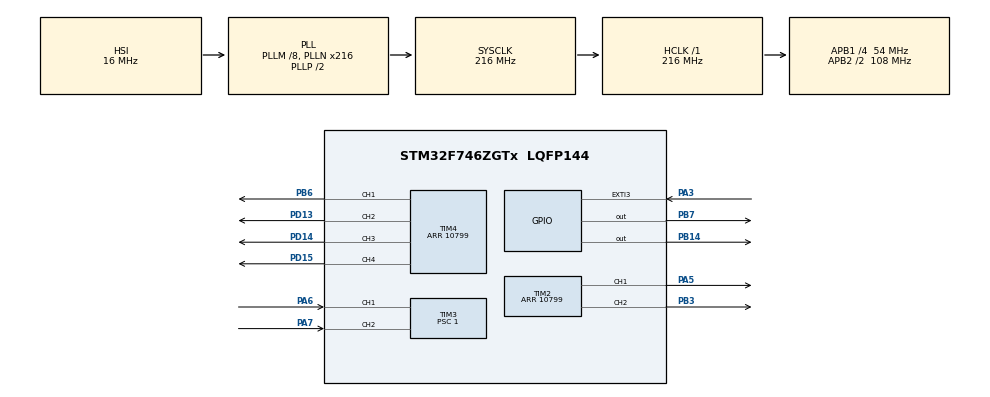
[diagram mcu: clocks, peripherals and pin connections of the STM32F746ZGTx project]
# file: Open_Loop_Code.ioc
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Mcu.Family=STM32F7
Mcu.Name=STM32F746ZGTx
Mcu.Package=LQFP144
NVIC.EXTI3_IRQn=true\:0\:0\:false\:false\:true\:true\:true
NVIC.PriorityGroup=NVIC_PRIORITYGROUP_4
NVIC.TIM5_IRQn=true\:0\:0\:false\:false\:true\:true\:true
PA3.Signal=GPXTI3
PA5.Signal=S_TIM2_CH1_ETR
PA6.Signal=S_TIM3_CH1
PA7.Signal=S_TIM3_CH2
PB14.Signal=GPIO_Output
PB3.Signal=S_TIM2_CH2
PB6.Signal=S_TIM4_CH1
PB7.Signal=GPIO_Output
PD13.Signal=S_TIM4_CH2
PD14.Signal=S_TIM4_CH3
PD15.Signal=S_TIM4_CH4
ProjectManager.HeapSize=0x200
ProjectManager.StackSize=0x400
ProjectManager.TargetToolchain=MDK-ARM V5.27
RCC.AHBFreq_Value=216000000
RCC.APB1CLKDivider=RCC_HCLK_DIV4
RCC.APB1Freq_Value=54000000
RCC.APB1TimFreq_Value=108000000
RCC.APB2CLKDivider=RCC_HCLK_DIV2
RCC.APB2Freq_Value=108000000
RCC.APB2TimFreq_Value=216000000
RCC.CortexFreq_Value=216000000
RCC.HCLKFreq_Value=216000000
RCC.HSE_VALUE=25000000
RCC.HSI_VALUE=16000000
RCC.LSE_VALUE=32768
RCC.PLLM=8
RCC.PLLN=216
RCC.SYSCLKFreq_VALUE=216000000
RCC.SYSCLKSource=RCC_SYSCLKSOURCE_PLLCLK
RCC.USBFreq_Value=216000000
RCC.VCOOutputFreq_Value=432000000
SH.S_TIM2_CH1_ETR.0=TIM2_CH1,PWM Generation1 CH1
SH.S_TIM2_CH2.0=TIM2_CH2,PWM Generation2 CH2
SH.S_TIM3_CH1.0=TIM3_CH1,Encoder_Interface
SH.S_TIM3_CH2.0=TIM3_CH2,Encoder_Interface
SH.S_TIM4_CH1.0=TIM4_CH1,PWM Generation1 CH1
SH.S_TIM4_CH2.0=TIM4_CH2,PWM Generation2 CH2
SH.S_TIM4_CH3.0=TIM4_CH3,PWM Generation3 CH3
SH.S_TIM4_CH4.0=TIM4_CH4,PWM Generation4 CH4
TIM2.Channel-PWM\ Generation1\ CH1=TIM_CHANNEL_1
TIM2.Channel-PWM\ Generation2\ CH2=TIM_CHANNEL_2
TIM2.CounterMode=TIM_COUNTERMODE_CENTERALIGNED1
TIM2.Period=10799
TIM3.EncoderMode=TIM_ENCODERMODE_TI12
TIM3.Period=65535
TIM3.Prescaler=1
TIM4.Channel-PWM\ Generation1\ CH1=TIM_CHANNEL_1
TIM4.Channel-PWM\ Generation2\ CH2=TIM_CHANNEL_2
TIM4.Channel-PWM\ Generation3\ CH3=TIM_CHANNEL_3
TIM4.Channel-PWM\ Generation4\ CH4=TIM_CHANNEL_4
TIM4.CounterMode=TIM_COUNTERMODE_CENTERALIGNED1
TIM4.Period=10799
TIM5.Period=49
TIM5.Prescaler=215
VP_TIM5_VS_ClockSourceINT.Mode=Internal
board=custom

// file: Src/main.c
/* USER CODE BEGIN Header */
/**
  ******************************************************************************
  * @file           : main.c
  * @brief          : Main program body
  ******************************************************************************
  * @attention
  *
  * <h2><center>&copy; Copyright (c) 2021 STMicroelectronics.
  * All rights reserved.</center></h2>
  *
  * This software component is licensed by ST under BSD 3-Clause license,
  * the "License"; You may not use this file except in compliance with the
  * License. You may obtain a copy of the License at:
  *                        opensource.org/licenses/BSD-3-Clause
  *
  ******************************************************************************
  */
/* USER CODE END Header */

#include "main.h"
#include "function.h"

TIM_HandleTypeDef htim5;

/* USER CODE BEGIN PV */
uint32_t flag=0;
float e_angle,r_angle,diff;
float b=0;
int vv,dc;
uint32_t EncoderPulseCount;
/* USER CODE END PV */

void SystemClock_Config(void);
static void MX_GPIO_Init(void);
static void MX_TIM5_Init(void);
/* USER CODE BEGIN PFP */
void HAL_TIM_PeriodElapsedCallback(TIM_HandleTypeDef *htim)
{
	  if(htim->Instance == TIM5)
		{
			HAL_GPIO_WritePin(GPIOB,GPIO_PIN_7,1);

			EncoderPulseCount=TIM3->CNT;

			encoder(b,&e_angle,&r_angle,&diff);

			voltage_vector(e_angle ,diff, &vv);
			PWM_Generation(vv,10);
			//theta_inital=r_angle;
			HAL_GPIO_WritePin(GPIOB,GPIO_PIN_7,0);

		}

 }
/* USER CODE END PFP */

int main(void)
{

  /* MCU Configuration--------------------------------------------------------*/

  /* Reset of all peripherals, Initializes the Flash interface and the Systick. */
HAL_Init();

  /* Configure the system clock */
  SystemClock_Config();

  /* Initialize all configured peripherals */
  MX_GPIO_Init();
  MX_TIM2_Init();
  MX_TIM3_Init();
  MX_TIM4_Init();
  MX_TIM5_Init();
HAL_TIM_Base_Start_IT(&htim5);
encoders_init();
encoders_define_home();
PWM_Init();

  /* Infinite loop */
  while (1)
  {

  }
}

void SystemClock_Config(void)
{
  RCC_OscInitTypeDef RCC_OscInitStruct = {0};
  RCC_ClkInitTypeDef RCC_ClkInitStruct = {0};

  /** Configure the main internal regulator output voltage
  */
  __HAL_RCC_PWR_CLK_ENABLE();
  __HAL_PWR_VOLTAGESCALING_CONFIG(PWR_REGULATOR_VOLTAGE_SCALE1);
  /** Initializes the CPU, AHB and APB busses clocks
  */
  RCC_OscInitStruct.OscillatorType = RCC_OSCILLATORTYPE_HSI;
  RCC_OscInitStruct.HSIState = RCC_HSI_ON;
  RCC_OscInitStruct.HSICalibrationValue = RCC_HSICALIBRATION_DEFAULT;
  RCC_OscInitStruct.PLL.PLLState = RCC_PLL_ON;
  RCC_OscInitStruct.PLL.PLLSource = RCC_PLLSOURCE_HSI;
  RCC_OscInitStruct.PLL.PLLM = 8;
  RCC_OscInitStruct.PLL.PLLN = 216;
  RCC_OscInitStruct.PLL.PLLP = RCC_PLLP_DIV2;
  RCC_OscInitStruct.PLL.PLLQ = 2;
  if (HAL_RCC_OscConfig(&RCC_OscInitStruct) != HAL_OK)
  {
    Error_Handler();
  }
  /** Activate the Over-Drive mode
  */
  if (HAL_PWREx_EnableOverDrive() != HAL_OK)
  {
    Error_Handler();
  }
  /** Initializes the CPU, AHB and APB busses clocks
  */
  RCC_ClkInitStruct.ClockType = RCC_CLOCKTYPE_HCLK|RCC_CLOCKTYPE_SYSCLK
                              |RCC_CLOCKTYPE_PCLK1|RCC_CLOCKTYPE_PCLK2;
  RCC_ClkInitStruct.SYSCLKSource = RCC_SYSCLKSOURCE_PLLCLK;
  RCC_ClkInitStruct.AHBCLKDivider = RCC_SYSCLK_DIV1;
  RCC_ClkInitStruct.APB1CLKDivider = RCC_HCLK_DIV4;
  RCC_ClkInitStruct.APB2CLKDivider = RCC_HCLK_DIV2;

  if (HAL_RCC_ClockConfig(&RCC_ClkInitStruct, FLASH_LATENCY_7) != HAL_OK)
  {
    Error_Handler();
  }
}

static void MX_TIM5_Init(void)
{

  TIM_ClockConfigTypeDef sClockSourceConfig = {0};
  TIM_MasterConfigTypeDef sMasterConfig = {0};

  htim5.Instance = TIM5;
  htim5.Init.Prescaler = 215;
  htim5.Init.CounterMode = TIM_COUNTERMODE_UP;
  htim5.Init.Period = 24;
  htim5.Init.ClockDivision = TIM_CLOCKDIVISION_DIV1;
  htim5.Init.AutoReloadPreload = TIM_AUTORELOAD_PRELOAD_DISABLE;
  if (HAL_TIM_Base_Init(&htim5) != HAL_OK)
  {
    Error_Handler();
  }
  sClockSourceConfig.ClockSource = TIM_CLOCKSOURCE_INTERNAL;
  if (HAL_TIM_ConfigClockSource(&htim5, &sClockSourceConfig) != HAL_OK)
  {
    Error_Handler();
  }
  sMasterConfig.MasterOutputTrigger = TIM_TRGO_RESET;
  sMasterConfig.MasterSlaveMode = TIM_MASTERSLAVEMODE_DISABLE;
  if (HAL_TIMEx_MasterConfigSynchronization(&htim5, &sMasterConfig) != HAL_OK)
  {
    Error_Handler();
  }

}

static void MX_GPIO_Init(void)
{
  GPIO_InitTypeDef GPIO_InitStruct = {0};

  /* GPIO Ports Clock Enable */
  __HAL_RCC_GPIOA_CLK_ENABLE();
  __HAL_RCC_GPIOB_CLK_ENABLE();
  __HAL_RCC_GPIOD_CLK_ENABLE();

  /*Configure GPIO pin Output Level */
  HAL_GPIO_WritePin(GPIOB, GPIO_PIN_14|GPIO_PIN_7, GPIO_PIN_RESET);

  /*Configure GPIO pin : PA3 */
  GPIO_InitStruct.Pin = GPIO_PIN_3;
  GPIO_InitStruct.Mode = GPIO_MODE_IT_RISING;
  GPIO_InitStruct.Pull = GPIO_NOPULL;
  HAL_GPIO_Init(GPIOA, &GPIO_InitStruct);

  /*Configure GPIO pins : PB14 PB7 */
  GPIO_InitStruct.Pin = GPIO_PIN_14|GPIO_PIN_7;
  GPIO_InitStruct.Mode = GPIO_MODE_OUTPUT_PP;
  GPIO_InitStruct.Pull = GPIO_NOPULL;
  GPIO_InitStruct.Speed = GPIO_SPEED_FREQ_LOW;
  HAL_GPIO_Init(GPIOB, &GPIO_InitStruct);

  /* EXTI interrupt init*/
  HAL_NVIC_SetPriority(EXTI3_IRQn, 0, 0);
  HAL_NVIC_EnableIRQ(EXTI3_IRQn);

}

void HAL_GPIO_EXTI_Callback(uint16_t GPIO_PIN)
{
	UNUSED(GPIO_PIN);
	HAL_GPIO_TogglePin(GPIOB,GPIO_PIN_14);
	TIM3->CNT=200;
}

void Error_Handler(void)
{
}

/************************ (C) COPYRIGHT STMicroelectronics *****END OF FILE****/
